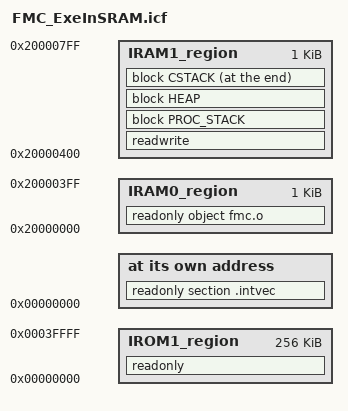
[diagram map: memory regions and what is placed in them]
/* --------------------------------------------------------------------------
 * IAR Linker Configuration File
 * Converted from FMC_ExeInSRAM.sct
 *
 * Keil scatter layout:
 *   Flash      : 0x00000000 - 0x0003FFFF (256 KB)
 *   SRAM total : 0x20000000 - 0x20007FFF ( 32 KB)
 *   SRAM0      : 0x20000000 - 0x20003FFF ( 16 KB) : fmc.o read-only code/data
 *   SRAM1      : 0x20004000 - 0x20007FFF ( 16 KB) : RW/ZI + heap + stack
 *   Stack      : 0x200 bytes, placed at end of SRAM1
 *   Heap       : 0x200 bytes
 * -------------------------------------------------------------------------- */

/*###ICF### Section handled by ICF editor, don't touch! ****/
/*-Editor annotation file-*/
/* IcfEditorFile="$TOOLKIT_DIR$\config\ide\IcfEditor\cortex_v1_4.xml" */

/*-Specials-*/
define symbol __ICFEDIT_intvec_start__ = 0x00000000;

/*-Memory Regions-*/
define symbol __ICFEDIT_region_IROM1_start__ = 0x00000000;
define symbol __ICFEDIT_region_IROM1_end__   = 0x0003FFFF;

define symbol __ICFEDIT_region_IRAM0_start__ = 0x20000000;
define symbol __ICFEDIT_region_IRAM0_end__   = 0x200003FF;

define symbol __ICFEDIT_region_IRAM1_start__ = 0x20000400;
define symbol __ICFEDIT_region_IRAM1_end__   = 0x200007FF;

/*-Sizes-*/
define symbol __ICFEDIT_size_cstack__     = 0x00000200;
define symbol __ICFEDIT_size_proc_stack__ = 0x00000000;
define symbol __ICFEDIT_size_heap__       = 0x00000200;
/**** End of ICF editor section. ###ICF###*/


define memory mem with size = 4G;

define region IROM1_region =
    mem:[from __ICFEDIT_region_IROM1_start__ to __ICFEDIT_region_IROM1_end__];

define region IRAM0_region =
    mem:[from __ICFEDIT_region_IRAM0_start__ to __ICFEDIT_region_IRAM0_end__];

define region IRAM1_region =
    mem:[from __ICFEDIT_region_IRAM1_start__ to __ICFEDIT_region_IRAM1_end__];


/* Stack / Heap */
define block CSTACK
    with alignment = 8, size = __ICFEDIT_size_cstack__ { };

define block PROC_STACK
    with alignment = 8, size = __ICFEDIT_size_proc_stack__ { };

define block HEAP
    with alignment = 8, size = __ICFEDIT_size_heap__ { };


/* Sections that must not be initialized */
do not initialize { section .noinit };

/*
 * fmc.o is executed from SRAM0.
 * Its readonly sections therefore need an initialization image in Flash and
 * are copied to SRAM during C runtime initialization.
 * Normal read/write data is also initialized by copy.
 */
initialize by copy { readonly object fmc.o, readwrite };

if (isdefinedsymbol(__USE_DLIB_PERTHREAD))
{
    initialize by copy with packing = none { section __DLIB_PERTHREAD };
}


/* Interrupt vector table stays at Flash address 0x00000000. */
place at address mem:__ICFEDIT_intvec_start__
{
    readonly section .intvec
};


/*
 * Equivalent of Keil:
 *     RW_RAM0 __RW_BASE __SRAM_SIZE0 { fmc.o (+RO) }
 *
 * Place every read-only section originating from fmc.o in SRAM0.
 */
place in IRAM0_region
{
    readonly object fmc.o
};


/*
 * All remaining read-only sections execute from Flash.
 * Explicitly exclude fmc.o because it belongs to IRAM0_region.
 */
place in IROM1_region
{
    readonly
}
except
{
    readonly object fmc.o
};


/*
 * Equivalent of Keil:
 *     RW_RAM1 (__RW_BASE + __SRAM_SIZE0) __SRAM_SIZE1 { .ANY (+RW +ZI) }
 *
 * RW/ZI and heap are placed in the upper 16 KB SRAM bank.
 */
place in IRAM1_region
{
    readwrite,
    block PROC_STACK,
    block HEAP
};


/* Keil ARM_LIB_STACK is located at the top of SRAM and grows downward. */
place at end of IRAM1_region
{
    block CSTACK
};
